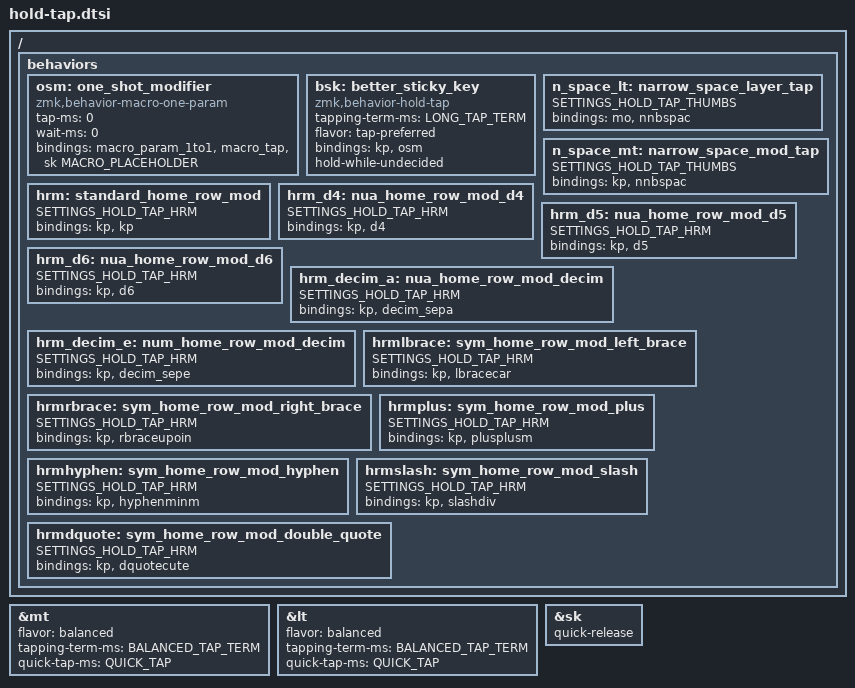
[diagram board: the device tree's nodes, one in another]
#define BALANCED_TAP_TERM 225
#define QUICK_TAP 225
#define LONG_TAP_TERM 300


#define SETTINGS_HOLD_TAP_THUMBS                            \
      compatible = "zmk,behavior-hold-tap";                 \
      #binding-cells = <2>;                                 \
      flavor = "balanced";                                  \
      tapping-term-ms = <BALANCED_TAP_TERM>;                \
      quick-tap-ms = <QUICK_TAP>

#define SETTINGS_HOLD_TAP_HRM                               \
      compatible = "zmk,behavior-hold-tap";                 \
      #binding-cells = <2>;                                 \
      flavor = "tap-preferred";                             \
      tapping-term-ms = <LONG_TAP_TERM>;                    \
      quick-tap-ms = <QUICK_TAP>

      
&mt {
  flavor = "balanced";
  tapping-term-ms = <BALANCED_TAP_TERM>;
  quick-tap-ms = <QUICK_TAP>;
};

&lt{
  flavor = "balanced";
  tapping-term-ms = <BALANCED_TAP_TERM>;
  quick-tap-ms = <QUICK_TAP>;
};

&sk {
    quick-release;
};


/ {
  behaviors {
      
    /* 
     * 
     * Sticky key from Selenium project - Nuclear-Squid's repos
     * https://github.com/Nuclear-Squid/zmk-keyboard-quacken/blob/main/keymaps/hold_taps.dtsi
     * 
     */
    
    // like ZMK's sticky key (sk) but with a more robust timing
    osm: one_shot_modifier {
      compatible = "zmk,behavior-macro-one-param";
      #binding-cells = <1>;
      tap-ms = <0>;
      wait-ms = <0>;
      bindings = <&macro_param_1to1>, <&macro_tap &sk MACRO_PLACEHOLDER>;
    };
    bsk: better_sticky_key {
      compatible = "zmk,behavior-hold-tap";
      #binding-cells = <2>;
      tapping-term-ms = <LONG_TAP_TERM>;
      flavor = "tap-preferred";
      bindings = <&kp>, <&osm>;     
      // hold-while-undecided added to the Selenium def
      hold-while-undecided;
    };
    
    /* 
     * 
     * Hold-taps for thumbs
     * 
     */
    
    // HRM for right thumb, center - Base layer emulated Ergo-L on Azerty
    n_space_lt: narrow_space_layer_tap {
      SETTINGS_HOLD_TAP_THUMBS;
      bindings =                            <&mo>,          <&nnbspac>      ;
    };
    
    // HRM for right thumb, center - NUM layer emulated Ergo-L on Azerty
    n_space_mt: narrow_space_mod_tap {
      SETTINGS_HOLD_TAP_THUMBS;
      bindings =                            <&kp>,          <&nnbspac>      ;
    };
    
    /* 
     * 
     * HRMs 
     * 
     */
    
    // Standard HRM (only with &kp, so not with mod-morph)
    hrm: standard_home_row_mod {
      SETTINGS_HOLD_TAP_HRM;
      bindings =                            <&kp>,          <&kp>           ;
    };
    
    /* 
     * 
     * NUM layer HRMs 
     * 
     */
    
    // HRM for right index - NUM layer emulated Ergo-L on Azerty
    hrm_d4: nua_home_row_mod_d4 {
      SETTINGS_HOLD_TAP_HRM;
      bindings =                            <&kp>,          <&d4>           ;
    };
    
    // HRM for right middle - NUM layer emulated Ergo-L on Azerty
    hrm_d5: nua_home_row_mod_d5 {
      SETTINGS_HOLD_TAP_HRM;
      bindings =                            <&kp>,          <&d5>           ;
    };
    
    // HRM for right ring - NUM layer emulated Ergo-L on Azerty
    hrm_d6: nua_home_row_mod_d6 {
      SETTINGS_HOLD_TAP_HRM;
      bindings =                            <&kp>,          <&d6>           ;
    };
    
    // HRM for right pinky - NUM layer emulated Ergo-L on Azerty
    hrm_decim_a: nua_home_row_mod_decim {
      SETTINGS_HOLD_TAP_HRM;
      bindings =                            <&kp>,          <&decim_sepa>   ;
    };
    
    // HRM for pinky - NUM layer direct Ergo-L
    hrm_decim_e: num_home_row_mod_decim {
      SETTINGS_HOLD_TAP_HRM;
      bindings =                            <&kp>,          <&decim_sepe>   ;
    };
    
    /* 
     * 
     * SYM layer HRMs 
     * 
     */
    
    // HRM for left pinky - SYM layer emulated Ergo-L on Azerty
    hrmlbrace: sym_home_row_mod_left_brace {
      SETTINGS_HOLD_TAP_HRM;
      bindings =                            <&kp>,          <&lbracecar>    ;
    };
    
    // HRM for left index - SYM layer emulated Ergo-L on Azerty
    hrmrbrace: sym_home_row_mod_right_brace {
      SETTINGS_HOLD_TAP_HRM;
      bindings =                            <&kp>,          <&rbraceupoin>  ;
    };
    
    // HRM for right index - SYM layer emulated Ergo-L on Azerty
    hrmplus: sym_home_row_mod_plus {
      SETTINGS_HOLD_TAP_HRM;
      bindings =                            <&kp>,          <&plusplusm>    ;
    };
    
    // HRM for right middle - SYM layer emulated Ergo-L on Azerty
    hrmhyphen: sym_home_row_mod_hyphen {
      SETTINGS_HOLD_TAP_HRM;
      bindings =                            <&kp>,          <&hyphenminm>   ;
    };
    
    // HRM for right ring - SYM layer emulated Ergo-L on Azerty
    hrmslash: sym_home_row_mod_slash {
      SETTINGS_HOLD_TAP_HRM;
      bindings =                            <&kp>,          <&slashdiv>     ;
    };
    
    // HRM for right pinky - SYM layer emulated Ergo-L on Azerty
    hrmdquote: sym_home_row_mod_double_quote {
      SETTINGS_HOLD_TAP_HRM;
      bindings =                            <&kp>,          <&dquotecute>   ;
    };
    
  };
};
